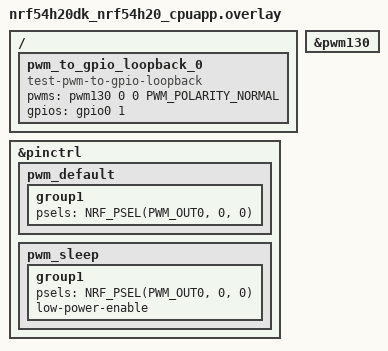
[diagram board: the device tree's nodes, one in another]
/ {
	pwm_to_gpio_loopback_0 {
		compatible = "test-pwm-to-gpio-loopback";
		pwms = <&pwm130 0 0 PWM_POLARITY_NORMAL>;
		gpios = <&gpio0 1 GPIO_ACTIVE_HIGH>;
	};
};


&pinctrl {
	pwm_default: pwm_default {
		group1 {
			psels = <NRF_PSEL(PWM_OUT0, 0, 0)>;
		};
	};
	pwm_sleep: pwm_sleep {
		group1 {
			psels = <NRF_PSEL(PWM_OUT0, 0, 0)>;
			low-power-enable;
		};
	};
};

&pwm130 {
	status = "okay";
};
